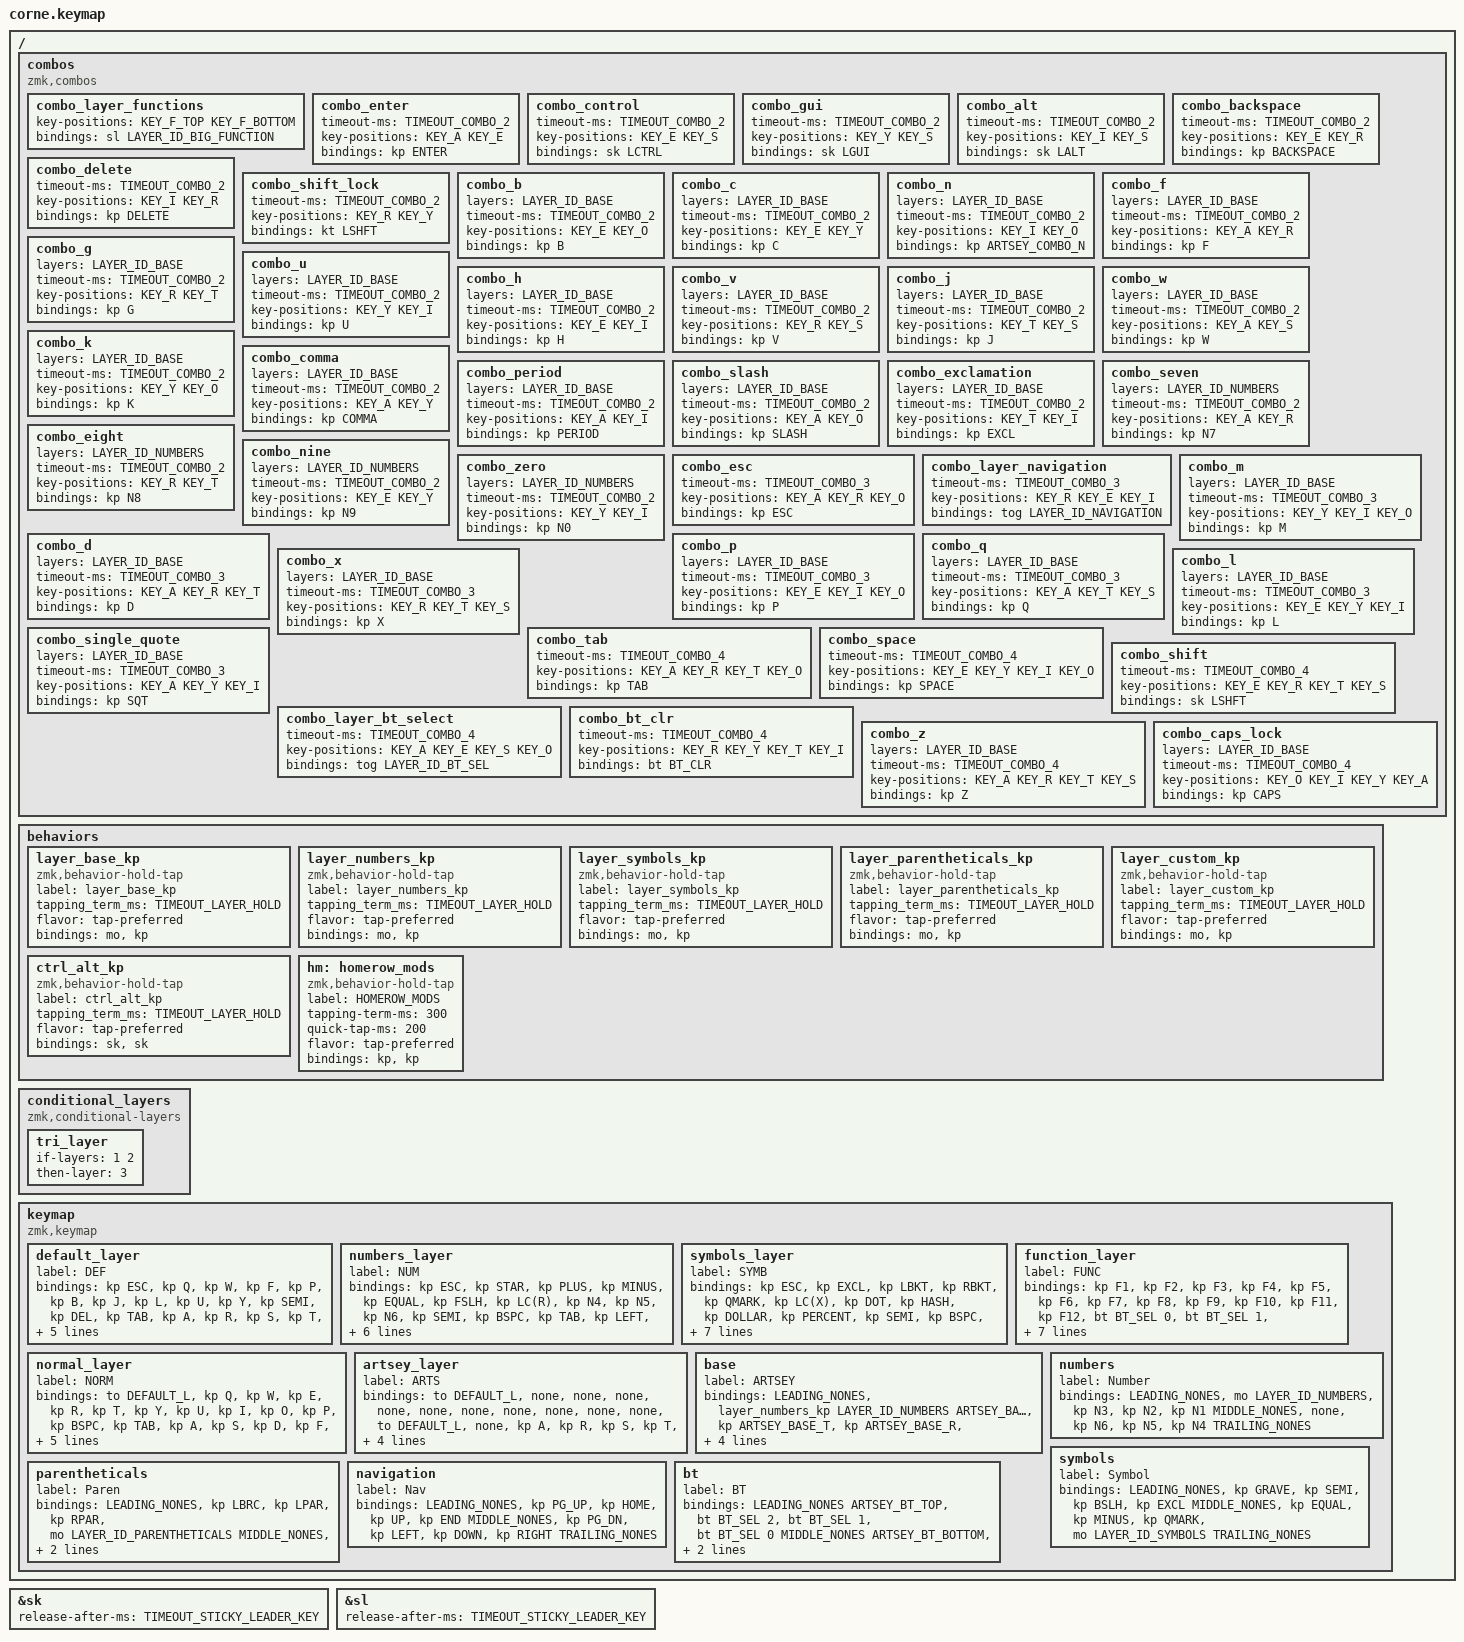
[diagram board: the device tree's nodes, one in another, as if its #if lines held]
/*
 * Copyright (c) 2020 The ZMK Contributors
 *
 * SPDX-License-Identifier: MIT
 */

#include <behaviors.dtsi>
#include <dt-bindings/zmk/keys.h>
#include <dt-bindings/zmk/bt.h>

#define DEFAULT_L 0
#define NUMBERS_L 1
#define SYMBOLS_L  2
#define FUNCTION_L 3
#define NORMAL_L 4
#define ARTSEY_L 5

// ARTSEY.IO stuf
#if !defined TIMEOUT_COMBO_2
#define TIMEOUT_COMBO_2 175
#endif
#if !defined TIMEOUT_COMBO_3
#define TIMEOUT_COMBO_3 175
#endif
#if !defined TIMEOUT_COMBO_4
#define TIMEOUT_COMBO_4 175
#endif
#if !defined TIMEOUT_LAYER_HOLD
#define TIMEOUT_LAYER_HOLD 200
#endif
#if !defined TIMEOUT_STICKY_LEADER_KEY
#define TIMEOUT_STICKY_LEADER_KEY 5000
#endif
&sk {
	release-after-ms = <TIMEOUT_STICKY_LEADER_KEY>;
};
&sl { 
	release-after-ms = <TIMEOUT_STICKY_LEADER_KEY>;
};

/ {
	combos {
		compatible = "zmk,combos";
		/*****************************************
		 * 2 key combos
		 *****************************************/
		// Function layer doesn't apply to non-big artsey presently
		#if defined ARTSEY_BIG
		combo_layer_functions { key-positions = <KEY_F_TOP KEY_F_BOTTOM>; bindings = <&sl LAYER_ID_BIG_FUNCTION>; };
		#endif
		combo_enter      { timeout-ms = <TIMEOUT_COMBO_2>; key-positions = <KEY_A KEY_E>; bindings = <&kp ENTER>; };
		combo_control    { timeout-ms = <TIMEOUT_COMBO_2>; key-positions = <KEY_E KEY_S>; bindings = <&sk LCTRL>; };
		combo_gui        { timeout-ms = <TIMEOUT_COMBO_2>; key-positions = <KEY_Y KEY_S>; bindings = <&sk LGUI>; };
		combo_alt        { timeout-ms = <TIMEOUT_COMBO_2>; key-positions = <KEY_I KEY_S>; bindings = <&sk LALT>; };
		combo_backspace  { timeout-ms = <TIMEOUT_COMBO_2>; key-positions = <KEY_E KEY_R>; bindings = <&kp BACKSPACE>; };
		combo_delete     { timeout-ms = <TIMEOUT_COMBO_2>; key-positions = <KEY_I KEY_R>; bindings = <&kp DELETE>; };
		combo_shift_lock { timeout-ms = <TIMEOUT_COMBO_2>; key-positions = <KEY_R KEY_Y>; bindings = <&kt LSHFT>; };

		combo_b           { layers = <LAYER_ID_BASE>; timeout-ms = <TIMEOUT_COMBO_2>; key-positions = <KEY_E KEY_O>; bindings = <&kp B>; };
		combo_c           { layers = <LAYER_ID_BASE>; timeout-ms = <TIMEOUT_COMBO_2>; key-positions = <KEY_E KEY_Y>; bindings = <&kp C>; };
		combo_n           { layers = <LAYER_ID_BASE>; timeout-ms = <TIMEOUT_COMBO_2>; key-positions = <KEY_I KEY_O>; bindings = <&kp ARTSEY_COMBO_N>; };
		combo_f           { layers = <LAYER_ID_BASE>; timeout-ms = <TIMEOUT_COMBO_2>; key-positions = <KEY_A KEY_R>; bindings = <&kp F>; };
		combo_g           { layers = <LAYER_ID_BASE>; timeout-ms = <TIMEOUT_COMBO_2>; key-positions = <KEY_R KEY_T>; bindings = <&kp G>; };
		combo_u           { layers = <LAYER_ID_BASE>; timeout-ms = <TIMEOUT_COMBO_2>; key-positions = <KEY_Y KEY_I>; bindings = <&kp U>; };
		combo_h           { layers = <LAYER_ID_BASE>; timeout-ms = <TIMEOUT_COMBO_2>; key-positions = <KEY_E KEY_I>; bindings = <&kp H>; };
		combo_v           { layers = <LAYER_ID_BASE>; timeout-ms = <TIMEOUT_COMBO_2>; key-positions = <KEY_R KEY_S>; bindings = <&kp V>; };
		combo_j           { layers = <LAYER_ID_BASE>; timeout-ms = <TIMEOUT_COMBO_2>; key-positions = <KEY_T KEY_S>; bindings = <&kp J>; };
		combo_w           { layers = <LAYER_ID_BASE>; timeout-ms = <TIMEOUT_COMBO_2>; key-positions = <KEY_A KEY_S>; bindings = <&kp W>; };
		combo_k           { layers = <LAYER_ID_BASE>; timeout-ms = <TIMEOUT_COMBO_2>; key-positions = <KEY_Y KEY_O>; bindings = <&kp K>; };
		combo_comma       { layers = <LAYER_ID_BASE>; timeout-ms = <TIMEOUT_COMBO_2>; key-positions = <KEY_A KEY_Y>; bindings = <&kp COMMA>; };
		combo_period      { layers = <LAYER_ID_BASE>; timeout-ms = <TIMEOUT_COMBO_2>; key-positions = <KEY_A KEY_I>; bindings = <&kp PERIOD>; };
		combo_slash       { layers = <LAYER_ID_BASE>; timeout-ms = <TIMEOUT_COMBO_2>; key-positions = <KEY_A KEY_O>; bindings = <&kp SLASH>; };
		combo_exclamation { layers = <LAYER_ID_BASE>; timeout-ms = <TIMEOUT_COMBO_2>; key-positions = <KEY_T KEY_I>; bindings = <&kp EXCL>; };
		
		combo_seven { layers = <LAYER_ID_NUMBERS>; timeout-ms = <TIMEOUT_COMBO_2>; key-positions = <KEY_A KEY_R>; bindings = <&kp N7>; };
		combo_eight { layers = <LAYER_ID_NUMBERS>; timeout-ms = <TIMEOUT_COMBO_2>; key-positions = <KEY_R KEY_T>; bindings = <&kp N8>; };
		combo_nine  { layers = <LAYER_ID_NUMBERS>; timeout-ms = <TIMEOUT_COMBO_2>; key-positions = <KEY_E KEY_Y>; bindings = <&kp N9>; };
		combo_zero  { layers = <LAYER_ID_NUMBERS>; timeout-ms = <TIMEOUT_COMBO_2>; key-positions = <KEY_Y KEY_I>; bindings = <&kp N0>; };

		/*****************************************
		 * 3 key combos
		 *****************************************/
		combo_esc              { timeout-ms = <TIMEOUT_COMBO_3>; key-positions = <KEY_A KEY_R KEY_O>; bindings = <&kp ESC>; };
		combo_layer_navigation { timeout-ms = <TIMEOUT_COMBO_3>; key-positions = <KEY_R KEY_E KEY_I>; bindings = <&tog LAYER_ID_NAVIGATION>; };

		combo_m            { layers = <LAYER_ID_BASE>; timeout-ms = <TIMEOUT_COMBO_3>; key-positions = <KEY_Y KEY_I KEY_O>; bindings = <&kp M>; };
		combo_d            { layers = <LAYER_ID_BASE>; timeout-ms = <TIMEOUT_COMBO_3>; key-positions = <KEY_A KEY_R KEY_T>; bindings = <&kp D>; };
		combo_p            { layers = <LAYER_ID_BASE>; timeout-ms = <TIMEOUT_COMBO_3>; key-positions = <KEY_E KEY_I KEY_O>; bindings = <&kp P>; };
		combo_q            { layers = <LAYER_ID_BASE>; timeout-ms = <TIMEOUT_COMBO_3>; key-positions = <KEY_A KEY_T KEY_S>; bindings = <&kp Q>; };
		combo_x            { layers = <LAYER_ID_BASE>; timeout-ms = <TIMEOUT_COMBO_3>; key-positions = <KEY_R KEY_T KEY_S>; bindings = <&kp X>; };
		combo_l            { layers = <LAYER_ID_BASE>; timeout-ms = <TIMEOUT_COMBO_3>; key-positions = <KEY_E KEY_Y KEY_I>; bindings = <&kp L>; };
		combo_single_quote { layers = <LAYER_ID_BASE>; timeout-ms = <TIMEOUT_COMBO_3>; key-positions = <KEY_A KEY_Y KEY_I>; bindings = <&kp SQT>; };
		
		/*****************************************
		 * 4 key combos
		 *****************************************/
		combo_tab             { timeout-ms = <TIMEOUT_COMBO_4>; key-positions = <KEY_A KEY_R KEY_T KEY_O>; bindings = <&kp TAB>; };
		combo_space           { timeout-ms = <TIMEOUT_COMBO_4>; key-positions = <KEY_E KEY_Y KEY_I KEY_O>; bindings = <&kp SPACE>; };
		combo_shift           { timeout-ms = <TIMEOUT_COMBO_4>; key-positions = <KEY_E KEY_R KEY_T KEY_S>; bindings = <&sk LSHFT>; };
		combo_layer_bt_select { timeout-ms = <TIMEOUT_COMBO_4>; key-positions = <KEY_A KEY_E KEY_S KEY_O>; bindings = <&tog LAYER_ID_BT_SEL>; };
		combo_bt_clr          { timeout-ms = <TIMEOUT_COMBO_4>; key-positions = <KEY_R KEY_Y KEY_T KEY_I>; bindings = <&bt BT_CLR>; };

		combo_z         { layers = <LAYER_ID_BASE>; timeout-ms = <TIMEOUT_COMBO_4>; key-positions = <KEY_A KEY_R KEY_T KEY_S>; bindings = <&kp Z>; };
		combo_caps_lock { layers = <LAYER_ID_BASE>; timeout-ms = <TIMEOUT_COMBO_4>; key-positions = <KEY_O KEY_I KEY_Y KEY_A>; bindings = <&kp CAPS>; };
	};
};

/ {
	behaviors {
		layer_base_kp: layer_base_kp { compatible = "zmk,behavior-hold-tap"; label = "layer_base_kp"; 
						#binding-cells = <2>; tapping_term_ms = <TIMEOUT_LAYER_HOLD>; flavor = "tap-preferred"; 
						bindings = <&mo>, <&kp>; };
		layer_numbers_kp: layer_numbers_kp { compatible = "zmk,behavior-hold-tap"; label = "layer_numbers_kp"; 
						#binding-cells = <2>; tapping_term_ms = <TIMEOUT_LAYER_HOLD>; flavor = "tap-preferred"; 
						bindings = <&mo>, <&kp>; };
		layer_symbols_kp: layer_symbols_kp { compatible = "zmk,behavior-hold-tap"; label = "layer_symbols_kp"; 
						#binding-cells = <2>; tapping_term_ms = <TIMEOUT_LAYER_HOLD>; flavor = "tap-preferred"; 
						bindings = <&mo>, <&kp>; };
		layer_parentheticals_kp: layer_parentheticals_kp { compatible = "zmk,behavior-hold-tap"; label = "layer_parentheticals_kp";
						#binding-cells = <2>; tapping_term_ms = <TIMEOUT_LAYER_HOLD>; flavor = "tap-preferred";
						bindings = <&mo>, <&kp>; };
		layer_custom_kp: layer_custom_kp { compatible = "zmk,behavior-hold-tap"; label = "layer_custom_kp";
						#binding-cells = <2>; tapping_term_ms = <TIMEOUT_LAYER_HOLD>; flavor = "tap-preferred";
						bindings = <&mo>, <&kp>; };
		ctrl_alt_kp: ctrl_alt_kp { compatible = "zmk,behavior-hold-tap"; label = "ctrl_alt_kp";
						#binding-cells = <2>; tapping_term_ms = <TIMEOUT_LAYER_HOLD>; flavor = "tap-preferred";
						bindings = <&sk>, <&sk>; };
	};
};

// END ARTSEYSTUF

/ {

	behaviors {
        hm: homerow_mods {
            compatible = "zmk,behavior-hold-tap";
            label = "HOMEROW_MODS";
            #binding-cells = <2>;
            tapping-term-ms = <300>;
            quick-tap-ms = <200>;
            flavor = "tap-preferred";
            bindings = <&kp>, <&kp>;
        };
    };
     	conditional_layers {
        compatible = "zmk,conditional-layers";
        tri_layer {
            if-layers = <1 2>;
            then-layer = <3>;
        };
    };
        keymap {
                compatible = "zmk,keymap";

                default_layer {
			label = "DEF";
                        bindings = <
   &kp ESC	&kp Q &kp W &kp F &kp P &kp B    &kp J &kp L &kp U     &kp Y   &kp SEMI  &kp DEL
   &kp TAB   	&kp A &kp R &kp S &kp T &kp G    &kp M &kp N &kp E     &kp I   &kp O     &kp RET
   &kp LALT     &kp Z &kp X &kp C &kp D &kp V    &kp K &kp H &kp COMMA &kp DOT &kp SQT   &kp LGUI 
             &kp LSHFT &kp BSPC &mo SYMBOLS_L    &mo NUMBERS_L &kp SPACE &kp LCTRL
                        >;
                };

                numbers_layer {
			label = "NUM";
                        bindings = <
   &kp ESC  &kp STAR &kp PLUS  &kp MINUS &kp EQUAL &kp FSLH     &kp LC(R) &kp N4 &kp N5 &kp N6 &kp SEMI  &kp BSPC
   &kp TAB  &kp LEFT &kp DOWN  &kp UP    &kp RIGHT &kp SPACE    &kp LC(Z) &kp N0 &kp N1 &kp N2 &kp N3    &kp RET
   &kp LALT &kp LT   &kp COMMA &kp DOT   &kp GT    &kp CAPS     &kp LC(S) &kp N7 &kp N8 &kp N9 &kp GRAVE &kp LGUI
                                   &kp LCTRL &kp LSHFT &none    &trans &to NORMAL_L &none
                        >;
                };

                symbols_layer {
			label = "SYMB";
                        bindings = <
   			
   &kp ESC  &kp EXCL &kp LBKT &kp RBKT &kp QMARK &kp LC(X)    &kp DOT   &kp HASH  &kp DOLLAR &kp PERCENT &kp SEMI &kp BSPC
   &kp TAB  &kp BSLH &kp LPAR &kp RPAR &kp FSLH  &kp LC(C)    &kp UNDER &kp EQUAL &kp MINUS  &kp PLUS    &kp STAR &kp RET
   &kp LALT &kp LT   &kp LBRC &kp RBRC &kp GT    &kp LC(V)    &kp COMMA &kp AT    &kp AMPS   &kp CARET   &kp SQT  &kp LGUI
                                 &none &to NORMAL_L &trans    &trans &kp LSHFT &kp LCTRL
			>;
                };

                function_layer {
			label = "FUNC";
                        bindings = < 
   &kp F1       &kp F2       &kp F3       &kp F4       &kp F5       &kp F6        &kp F7       &kp F8       &kp F9    &kp F10    &kp F11      &kp F12
   &bt BT_SEL 0 &bt BT_SEL 1 &bt BT_SEL 2 &bt BT_SEL 3 &bt BT_SEL 4 &bt BT_CLR    &kp C_PREV   &kp C_VOL_DN &kp C_PP  &kp C_MUTE &kp C_VOL_UP &kp C_NEXT
   &kp INS      &sk LGUI     &sk LALT     &sk LCTRL    &sk LSHFT    &kp PSCRN     &kp C_BRI_DN &sk RSHFT    &sk RCTRL &sk RALT   &sk RGUI     &kp C_BRI_UP
                                        	     &to ARTSEY_L &none &trans    &trans &none &none
                        >;
                };
		
		normal_layer {
			label = "NORM";
                        bindings = <
   &to DEFAULT_L &kp Q &kp W &kp E &kp R &kp T    &kp Y &kp U &kp I     &kp O    &kp P    &kp BSPC
   &kp TAB    	 &kp A &kp S &kp D &kp F &kp G    &kp H &kp J &kp K     &kp L    &kp SEMI &kp SQT
   &kp LALT      &kp Z &kp X &kp C &kp V &kp B    &kp N &kp M &kp LEFT  &kp UP   &kp DOWN &kp RIGHT 
                      &kp N0 &kp DOT &kp LSHFT    &kp LCTRL &kp SPACE &kp N1
                        >;
                };

		artsey_layer {
			label = "ARTS";
			bindings = <
   &to DEFAULT_L &none &none &none &none &none    &none &none &none &none &none &to DEFAULT_L
   &none	 &kp A &kp R &kp S &kp T &none    &none &kp T &kp S &kp R &kp A &none
   &none	 &kp O &kp I &kp E &kp N &none    &none &kp N &kp E &kp I &kp O &none
                     	     &none &none &none    &none &none &none
			>;
		};

		base {
			label = "ARTSEY";
			bindings = <
				LEADING_NONES
				&layer_numbers_kp LAYER_ID_NUMBERS ARTSEY_BASE_S        &kp ARTSEY_BASE_T     &kp ARTSEY_BASE_R     &layer_parentheticals_kp LAYER_ID_PARENTHETICALS ARTSEY_BASE_A
				MIDDLE_NONES
				&layer_custom_kp LAYER_ID_CUSTOM ARTSEY_BASE_O          &kp ARTSEY_BASE_I     &kp ARTSEY_BASE_Y     &layer_symbols_kp LAYER_ID_SYMBOLS ARTSEY_BASE_E
				TRAILING_NONES
				#if defined CUSTOM_THUMB
				CUSTOM_THUMB
				#endif
			>;
		};
		numbers {
			label = "Number";
			bindings = <
				LEADING_NONES
				&mo LAYER_ID_NUMBERS                        &kp N3    &kp N2    &kp N1
				MIDDLE_NONES
				&none                                       &kp N6    &kp N5    &kp N4
				TRAILING_NONES
			>;
		};
		symbols {
			label = "Symbol";
			bindings = <
				LEADING_NONES
				&kp GRAVE                                   &kp SEMI  &kp BSLH  &kp EXCL
				MIDDLE_NONES
				&kp EQUAL                                   &kp MINUS &kp QMARK &mo LAYER_ID_SYMBOLS
				TRAILING_NONES
			>;
		};
		parentheticals {
			label = "Paren";
			bindings = <
				LEADING_NONES
				&kp LBRC                                    &kp LPAR  &kp RPAR  &mo LAYER_ID_PARENTHETICALS
				MIDDLE_NONES
				&kp RBRC                                    &kp LBKT  &kp RBKT  &none
				TRAILING_NONES
			>;
		};
		navigation {
			label = "Nav";
			bindings = <
				LEADING_NONES
				&kp PG_UP                                   &kp HOME  &kp UP    &kp END
				MIDDLE_NONES
				&kp PG_DN                                   &kp LEFT  &kp DOWN  &kp RIGHT
				TRAILING_NONES
			>;
		};
		bt {
			label = "BT";
			bindings = <
				LEADING_NONES
				ARTSEY_BT_TOP    &bt BT_SEL 2 &bt BT_SEL 1 &bt BT_SEL 0
				MIDDLE_NONES
				ARTSEY_BT_BOTTOM &bt BT_SEL 5 &bt BT_SEL 4 &bt BT_SEL 3
				TRAILING_NONES
			>;
		};

        };
};
